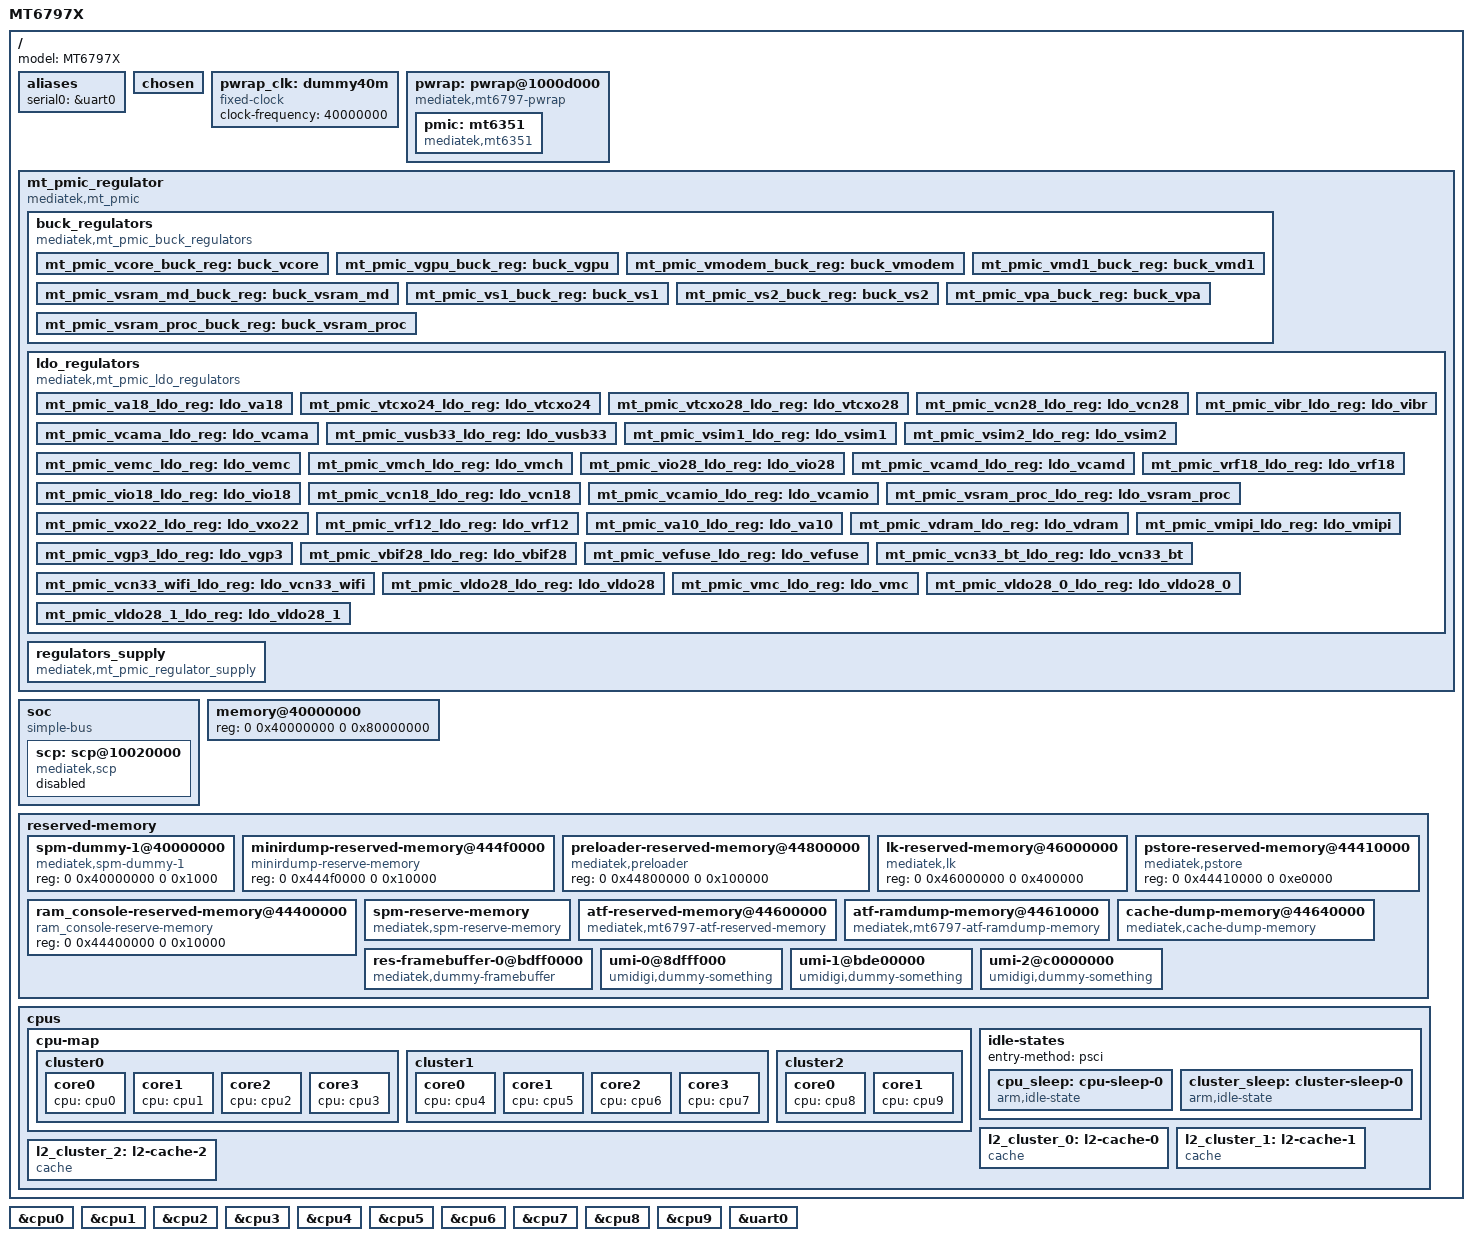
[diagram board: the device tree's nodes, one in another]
// SPDX-License-Identifier: GPL-2.0
/dts-v1/;

// This file will be copied to arch/arm64/boot/dts/gemini.dts by buildroot,
// so the include path must be relative to that.
#include "mediatek/mt6797.dtsi"
#include <dt-bindings/interrupt-controller/arm-gic.h>
#include <dt-bindings/power/mt6797-power.h>
#include <dt-bindings/reset/mt6797-resets.h>

/ {
	model = "MT6797X";

	aliases {
		serial0 = &uart0;
	};

	chosen {
		// Specifying cmdline here is useless, since they are
		// overwritten by LK. CMDLINE is overridden in kernel config.
	};

	// pwrap needs a pwrap clock, but MT6797 does not have one. Make a
	// fake clock to sate the module's hunger.
	pwrap_clk: dummy40m {
		compatible = "fixed-clock";
		clock-frequency = <40000000>;
		#clock-cells = <0>;
	};

	pwrap: pwrap@1000d000 {
		compatible = "mediatek,mt6797-pwrap";
		reg = <0 0x1000d000 0 0x1000>;
		reg-names = "pwrap";
		interrupts = <GIC_SPI 178 IRQ_TYPE_LEVEL_HIGH>;
		clocks = <&topckgen CLK_TOP_MUX_PMICSPI>, <&pwrap_clk>;
		clock-names = "spi", "wrap";
		resets = <&infrasys MT6797_INFRA_PMIC_WRAP_RST>;
		reset-names = "pwrap";
		pmic: mt6351 {
			compatible = "mediatek,mt6351";
		};
	};

	mt_pmic_regulator {
		compatible = "mediatek,mt_pmic";
		/*reg = <0x01>*/
		buck_regulators {
			compatible = "mediatek,mt_pmic_buck_regulators";
			mt_pmic_vcore_buck_reg: buck_vcore {
				regulator-name = "vcore";
				regulator-min-microvolt = <600000>;
				regulator-max-microvolt = <1393750>;
				regulator-ramp-delay = <6250>;
				regulator-enable-ramp-delay = <180>;
			};

			mt_pmic_vgpu_buck_reg: buck_vgpu {
				regulator-name = "vgpu";
				regulator-min-microvolt = <600000>;
				regulator-max-microvolt = <1393750>;
				regulator-ramp-delay = <6250>;
				regulator-enable-ramp-delay = <180>;
				regulator-always-on;
				regulator-boot-on;
			};

			mt_pmic_vmodem_buck_reg: buck_vmodem {
				regulator-name = "vmodem";
				regulator-min-microvolt = <600000>;
				regulator-max-microvolt = <1393750>;
				regulator-ramp-delay = <6250>;
				regulator-enable-ramp-delay = <180>;
				regulator-always-on;
				regulator-boot-on;
			};

			mt_pmic_vmd1_buck_reg: buck_vmd1 {
				regulator-name = "vmd1";
				regulator-min-microvolt = <600000>;
				regulator-max-microvolt = <1393750>;
				regulator-ramp-delay = <6250>;
				regulator-enable-ramp-delay = <180>;
				regulator-always-on;
				regulator-boot-on;
			};

			mt_pmic_vsram_md_buck_reg: buck_vsram_md {
				regulator-name = "vsram_md";
				regulator-min-microvolt = <600000>;
				regulator-max-microvolt = <1393750>;
				regulator-ramp-delay = <6250>;
				regulator-enable-ramp-delay = <180>;
				regulator-always-on;
				regulator-boot-on;
			};

			mt_pmic_vs1_buck_reg: buck_vs1 {
				regulator-name = "vs1";
				regulator-min-microvolt = <600000>;
				regulator-max-microvolt = <1393750>;
				regulator-ramp-delay = <6250>;
				regulator-enable-ramp-delay = <180>;
				regulator-always-on;
				regulator-boot-on;
			};

			mt_pmic_vs2_buck_reg: buck_vs2 {
				regulator-name = "vs2";
				regulator-min-microvolt = <600000>;
				regulator-max-microvolt = <1393750>;
				regulator-ramp-delay = <6250>;
				regulator-enable-ramp-delay = <180>;
				regulator-always-on;
				regulator-boot-on;
			};

			mt_pmic_vpa_buck_reg: buck_vpa {
				regulator-name = "vpa";
				regulator-min-microvolt = <600000>;
				regulator-max-microvolt = <1393750>;
				regulator-ramp-delay = <6250>;
				regulator-enable-ramp-delay = <180>;
				regulator-always-on;
				regulator-boot-on;
			};

			mt_pmic_vsram_proc_buck_reg: buck_vsram_proc {
				regulator-name = "vsram_proc";
				regulator-min-microvolt = <600000>;
				regulator-max-microvolt = <1393750>;
				regulator-ramp-delay = <6250>;
				regulator-enable-ramp-delay = <180>;
				regulator-always-on;
				regulator-boot-on;
			};

		};
	/* End of buck_regulators */
		ldo_regulators {
			compatible = "mediatek,mt_pmic_ldo_regulators";
			mt_pmic_va18_ldo_reg: ldo_va18 {
				regulator-name = "va18";
				regulator-min-microvolt = <1800000>;
				regulator-max-microvolt = <1800000>;
				regulator-enable-ramp-delay = <264>;
				regulator-boot-on;
			};

			mt_pmic_vtcxo24_ldo_reg: ldo_vtcxo24 {
				regulator-name = "vtcxo24";
				regulator-min-microvolt = <1800000>;
				regulator-max-microvolt = <2800000>;
				regulator-enable-ramp-delay = <110>;
				regulator-boot-on;
			};

			mt_pmic_vtcxo28_ldo_reg: ldo_vtcxo28 {
				regulator-name = "vtcxo28";
				regulator-min-microvolt = <1800000>;
				regulator-max-microvolt = <2800000>;
				regulator-enable-ramp-delay = <110>;
			};

			mt_pmic_vcn28_ldo_reg: ldo_vcn28 {
				regulator-name = "vcn28";
				regulator-min-microvolt = <1800000>;
				regulator-max-microvolt = <2800000>;
				regulator-enable-ramp-delay = <264>;
			};

			mt_pmic_vcama_ldo_reg: ldo_vcama {
				regulator-name = "vcama";
				regulator-min-microvolt = <1500000>;
				regulator-max-microvolt = <2800000>;
				regulator-enable-ramp-delay = <264>;
			};

			mt_pmic_vusb33_ldo_reg: ldo_vusb33 {
				regulator-name = "vusb33";
				regulator-min-microvolt = <3300000>;
				regulator-max-microvolt = <3300000>;
				regulator-enable-ramp-delay = <264>;
				regulator-boot-on;
			};

			mt_pmic_vsim1_ldo_reg: ldo_vsim1 {
				regulator-name = "vsim1";
				regulator-min-microvolt = <1700000>;
				regulator-max-microvolt = <3100000>;
				regulator-enable-ramp-delay = <264>;
			};

			mt_pmic_vsim2_ldo_reg: ldo_vsim2 {
				regulator-name = "vsim2";
				regulator-min-microvolt = <1700000>;
				regulator-max-microvolt = <3100000>;
				regulator-enable-ramp-delay = <264>;
			};

			mt_pmic_vemc_ldo_reg: ldo_vemc {
				regulator-name = "vemc_3v3";
				regulator-min-microvolt = <3000000>;
				regulator-max-microvolt = <3300000>;
				regulator-enable-ramp-delay = <44>;
				regulator-boot-on;
			};

			mt_pmic_vmch_ldo_reg: ldo_vmch {
				regulator-name = "vmch";
				regulator-min-microvolt = <3000000>;
				regulator-max-microvolt = <3300000>;
				regulator-enable-ramp-delay = <44>;
			};

			mt_pmic_vio28_ldo_reg: ldo_vio28 {
				regulator-name = "vio28";
				regulator-min-microvolt = <2800000>;
				regulator-max-microvolt = <2800000>;
				regulator-enable-ramp-delay = <264>;
				regulator-boot-on;
			};

			mt_pmic_vibr_ldo_reg: ldo_vibr {
				regulator-name = "vibr";
				regulator-min-microvolt = <1200000>;
				regulator-max-microvolt = <3300000>;
				regulator-enable-ramp-delay = <44>;
			};

			mt_pmic_vcamd_ldo_reg: ldo_vcamd {
				regulator-name = "vcamd";
				regulator-min-microvolt = <900000>;
				regulator-max-microvolt = <1210000>;
				regulator-enable-ramp-delay = <264>;
			};

			mt_pmic_vrf18_ldo_reg: ldo_vrf18 {
				regulator-name = "vrf18";
				regulator-min-microvolt = <1000000>;
				regulator-max-microvolt = <1810000>;
				regulator-enable-ramp-delay = <220>;
			};

			mt_pmic_vio18_ldo_reg: ldo_vio18 {
				regulator-name = "vio18";
				regulator-min-microvolt = <1800000>;
				regulator-max-microvolt = <1800000>;
				regulator-enable-ramp-delay = <264>;
				regulator-boot-on;
			};

			mt_pmic_vcn18_ldo_reg: ldo_vcn18 {
				regulator-name = "vcn18";
				regulator-min-microvolt = <1800000>;
				regulator-max-microvolt = <1800000>;
				regulator-enable-ramp-delay = <44>;
			};

			mt_pmic_vcamio_ldo_reg: ldo_vcamio {
				regulator-name = "vcamio";
				regulator-min-microvolt = <1200000>;
				regulator-max-microvolt = <1800000>;
				regulator-enable-ramp-delay = <220>;
			};

			mt_pmic_vsram_proc_ldo_reg: ldo_vsram_proc {
				regulator-name = "vsram_proc";
				regulator-min-microvolt = <600000>;
				regulator-max-microvolt = <1393750>;
				regulator-enable-ramp-delay = <220>;
				regulator-boot-on;
			};

			mt_pmic_vxo22_ldo_reg: ldo_vxo22 {
				regulator-name = "vxo22";
				regulator-min-microvolt = <1800000>;
				regulator-max-microvolt = <2800000>;
				regulator-enable-ramp-delay = <110>;
				regulator-boot-on;
			};

			mt_pmic_vrf12_ldo_reg: ldo_vrf12 {
				regulator-name = "vrf12";
				regulator-min-microvolt = <900000>;
				regulator-max-microvolt = <1200000>;
				regulator-enable-ramp-delay = <220>;
			};

			mt_pmic_va10_ldo_reg: ldo_va10 {
				regulator-name = "va10";
				regulator-min-microvolt = <900000>;
				regulator-max-microvolt = <1800000>;
				regulator-enable-ramp-delay = <264>;
				regulator-boot-on;
			};

			mt_pmic_vdram_ldo_reg: ldo_vdram {
				regulator-name = "vdram";
				regulator-min-microvolt = <900000>;
				regulator-max-microvolt = <1210000>;
				regulator-enable-ramp-delay = <264>;
			};

			mt_pmic_vmipi_ldo_reg: ldo_vmipi {
				regulator-name = "vmipi";
				regulator-min-microvolt = <900000>;
				regulator-max-microvolt = <1800000>;
				regulator-enable-ramp-delay = <264>;
			};

			mt_pmic_vgp3_ldo_reg: ldo_vgp3 {
				regulator-name = "vgp3";
				regulator-min-microvolt = <1000000>;
				regulator-max-microvolt = <1810000>;
				regulator-enable-ramp-delay = <264>;
			};

			mt_pmic_vbif28_ldo_reg: ldo_vbif28 {
				regulator-name = "vbif28";
				regulator-min-microvolt = <2800000>;
				regulator-max-microvolt = <2800000>;
				regulator-enable-ramp-delay = <264>;
			};

			mt_pmic_vefuse_ldo_reg: ldo_vefuse {
				regulator-name = "vefuse";
				regulator-min-microvolt = <1200000>;
				regulator-max-microvolt = <2200000>;
				regulator-enable-ramp-delay = <264>;
			};

			mt_pmic_vcn33_bt_ldo_reg: ldo_vcn33_bt {
				regulator-name = "vcn33_bt";
				regulator-min-microvolt = <3300000>;
				regulator-max-microvolt = <3600000>;
				regulator-enable-ramp-delay = <264>;
			};

			mt_pmic_vcn33_wifi_ldo_reg: ldo_vcn33_wifi {
				regulator-name = "vcn33_wifi";
				regulator-min-microvolt = <3300000>;
				regulator-max-microvolt = <3600000>;
				regulator-enable-ramp-delay = <264>;
			};

			mt_pmic_vldo28_ldo_reg: ldo_vldo28 {
				regulator-name = "vldo28";
				regulator-min-microvolt = <2800000>;
				regulator-max-microvolt = <2800000>;
				regulator-enable-ramp-delay = <264>;
			};

			mt_pmic_vmc_ldo_reg: ldo_vmc {
				regulator-name = "vmc";
				regulator-min-microvolt = <1200000>;
				regulator-max-microvolt = <3300000>;
				regulator-enable-ramp-delay = <44>;
			};

			mt_pmic_vldo28_0_ldo_reg: ldo_vldo28_0 {
				regulator-name = "vldo28_0";
				regulator-min-microvolt = <2800000>;
				regulator-max-microvolt = <2800000>;
				regulator-enable-ramp-delay = <264>;
			};

			mt_pmic_vldo28_1_ldo_reg: ldo_vldo28_1 {
				regulator-name = "vldo28_1";
				regulator-min-microvolt = <2800000>;
				regulator-max-microvolt = <2800000>;
				regulator-enable-ramp-delay = <264>;
			};

		};
/* End of ldo_regulators */
		regulators_supply {
			compatible = "mediatek,mt_pmic_regulator_supply";
			va18-supply = <&mt_pmic_va18_ldo_reg>;
			vtcxo24-supply = <&mt_pmic_vtcxo24_ldo_reg>;
			vtcxo28-supply = <&mt_pmic_vtcxo28_ldo_reg>;
			vsim1-supply = <&mt_pmic_vsim1_ldo_reg>;
			vsim2-supply = <&mt_pmic_vsim2_ldo_reg>;
			vemc-supply = <&mt_pmic_vemc_ldo_reg>;
			vmch-supply = <&mt_pmic_vmch_ldo_reg>;
			vmc-supply = <&mt_pmic_vmc_ldo_reg>;
			vio28-supply = <&mt_pmic_vio28_ldo_reg>;
			vibr-supply = <&mt_pmic_vibr_ldo_reg>;
			vrf18-supply = <&mt_pmic_vrf18_ldo_reg>;
			vio18-supply = <&mt_pmic_vio18_ldo_reg>;
			vsram_proc-supply = <&mt_pmic_vsram_proc_ldo_reg>;
			vxo22-supply = <&mt_pmic_vxo22_ldo_reg>;
			vrf12-supply = <&mt_pmic_vrf12_ldo_reg>;
			vdram-supply = <&mt_pmic_vdram_ldo_reg>;
			vmipi-supply = <&mt_pmic_vmipi_ldo_reg>;
			vbif28-supply = <&mt_pmic_vbif28_ldo_reg>;
			vefuse-supply = <&mt_pmic_vefuse_ldo_reg>;
			vcn18-supply = <&mt_pmic_vcn18_ldo_reg>;
			vcn28-supply = <&mt_pmic_vcn28_ldo_reg>;
			vcn33_bt-supply = <&mt_pmic_vcn33_bt_ldo_reg>;
			vcn33_wifi-supply = <&mt_pmic_vcn33_wifi_ldo_reg>;
			mhl_12v-supply = <&mt_pmic_vgp3_ldo_reg>;
		};
/* End of regulators_supply */
	};
/* End of mt_pmic_regulator */

	soc {
		compatible = "simple-bus";
		#address-cells = <1>;
		#size-cells = <1>;
		ranges = <0 0 0 0xffffffff>;

		// This node is required by MediaTek's LK bootloader.
		scp: scp@10020000 {
			compatible = "mediatek,scp";
			status = "disabled";
			reg = <0x10020000 0x80000>,
				<0x100a0000 0x1000>,
				<0x100a4000 0x1000>;
			interrupts = <GIC_SPI 199 IRQ_TYPE_LEVEL_HIGH>;
		};
	};

	memory@40000000 {
		device_type = "memory";
		// It won't matter much what we write here, since the bootloader
		// overwrites the reg option anyway.
		reg = <0 0x40000000 0 0x80000000>;
	};

	reserved-memory {
		#address-cells = <2>;
		#size-cells = <2>;
		ranges;

		spm-dummy-1@40000000 {
			compatible = "mediatek,spm-dummy-1";
			reg = <0 0x40000000 0 0x1000>;
		};

		minirdump-reserved-memory@444f0000 {
			compatible = "minirdump-reserve-memory";
			reg = <0 0x444f0000 0 0x10000>;
		};

		preloader-reserved-memory@44800000 {
			compatible = "mediatek,preloader";
			reg = <0 0x44800000 0 0x100000>;
		};

		lk-reserved-memory@46000000 {
			compatible = "mediatek,lk";
			reg = <0 0x46000000 0 0x400000>;
		};

		ram_console-reserved-memory@44400000 {
			compatible = "ram_console-reserve-memory";
			reg = <0 0x44400000 0 0x10000>;
		};

		pstore-reserved-memory@44410000 {
			compatible = "mediatek,pstore";
			reg = <0 0x44410000 0 0xe0000>;
			/*console-size = <0 0x40000>;*/
		};

		spm-reserve-memory {
			compatible = "mediatek,spm-reserve-memory";
			no-map;
			size = <0 0x16000>; /* PCM_FIRMWARE_SIZE * DYNA_LOAD_PCM_MAX = 8K * 11 */
			alignment = <0 0x10000>;
			alloc-ranges = <0 0x40000000 0 0x80000000>;
		};

		atf-reserved-memory@44600000 {
			compatible = "mediatek,mt6797-atf-reserved-memory";
			no-map;
			reg = <0 0x44600000 0 0x10000>;
		};

		atf-ramdump-memory@44610000 {
			compatible = "mediatek,mt6797-atf-ramdump-memory";
			no-map;
			reg = <0 0x44610000 0 0x30000>;
		};

		cache-dump-memory@44640000 {
			compatible = "mediatek,cache-dump-memory";
			no-map;
			reg = <0 0x44640000 0 0x30000>;
		};

		// These areas are not declared as reserved by the bootloader,
		// are not in the I/O range. They are ioremapped by the video
		// driver (during late boot).
		res-framebuffer-0@bdff0000 {
			compatible = "mediatek,dummy-framebuffer";
			no-map;
			reg = <0 0xbdff0000 0 0x01f90000>;
		};

		umi-0@8dfff000 {
			compatible = "umidigi,dummy-something";
			no-map;
			reg = <0 0x8dfff000 0 0x1000>;
		};

		umi-1@bde00000 {
			compatible = "umidigi,dummy-something";
			no-map;
			reg = <0 0xbde00000 0 0x10000>;
		};

		umi-2@c0000000 {
			compatible = "umidigi,dummy-something";
			no-map;
			// WTF 1.5 gigs?
			reg = <0 0xc0000000 0 0x60000000>;
		};
	};

	cpus {
		cpu-map {
			cluster0 {
				 core0 { cpu = <&cpu0>; };
				 core1 { cpu = <&cpu1>; };
				 core2 { cpu = <&cpu2>; };
				 core3 { cpu = <&cpu3>; };
			};
			cluster1 {
				 core0 { cpu = <&cpu4>; };
				 core1 { cpu = <&cpu5>; };
				 core2 { cpu = <&cpu6>; };
				 core3 { cpu = <&cpu7>; };
			};
			cluster2 {
				 core0 { cpu = <&cpu8>; };
				 core1 { cpu = <&cpu9>; };
			};
		};

		idle-states {
			entry-method = "psci";

			cpu_sleep: cpu-sleep-0 {
				compatible = "arm,idle-state";
				arm,psci-suspend-param = <0x0010000>;
				entry-latency-us = <600>;
				exit-latency-us = <600>;
				min-residency-us = <1200>;
			};
			cluster_sleep: cluster-sleep-0 {
				compatible = "arm,idle-state";
				arm,psci-suspend-param = <0x1010000>;
				entry-latency-us = <800>;
				exit-latency-us = <1000>;
				min-residency-us = <2000>;
			};
		};

		l2_cluster_0: l2-cache-0 {
			compatible = "cache";
			cache-size = <0x80000>;
			cache-line-size = <64>;
			cache-sets = <512>;
		};

		l2_cluster_1: l2-cache-1 {
			compatible = "cache";
			cache-size = <0x80000>;
			cache-line-size = <64>;
			cache-sets = <512>;
		};

		l2_cluster_2: l2-cache-2 {
			compatible = "cache";
			cache-size = <0x80000>;
			cache-line-size = <64>;
			cache-sets = <512>;
		};
	};
};

// clock-frequency must be specified for each CPU. If it is omitted, MediaTek's
// LK bootloader might read uninitialized memory and perhaps overwrite some
// random properties in the device tree.

// Slow Cortex-A53 cluster
&cpu0 {
	clock-frequency = <1391000000>;
	//cpu-idle-states = <&cpu_sleep &cluster_sleep>;
	i-cache-size = <0x8000>;
	i-cache-line-size = <64>;
	i-cache-sets = <256>;
	d-cache-size = <0x8000>;
	d-cache-line-size = <64>;
	d-cache-sets = <128>;
	next-level-cache = <&l2_cluster_0>;
};
&cpu1 {
	clock-frequency = <1391000000>;
	//cpu-idle-states = <&cpu_sleep &cluster_sleep>;
	i-cache-size = <0x8000>;
	i-cache-line-size = <64>;
	i-cache-sets = <256>;
	d-cache-size = <0x8000>;
	d-cache-line-size = <64>;
	d-cache-sets = <128>;
	next-level-cache = <&l2_cluster_0>;
};
&cpu2 {
	clock-frequency = <1391000000>;
	//cpu-idle-states = <&cpu_sleep &cluster_sleep>;
	i-cache-size = <0x8000>;
	i-cache-sets = <256>;
	i-cache-line-size = <64>;
	d-cache-size = <0x8000>;
	d-cache-line-size = <64>;
	d-cache-sets = <128>;
	next-level-cache = <&l2_cluster_0>;
};
&cpu3 {
	clock-frequency = <1391000000>;
	//cpu-idle-states = <&cpu_sleep &cluster_sleep>;
	i-cache-size = <0x8000>;
	i-cache-line-size = <64>;
	i-cache-sets = <256>;
	d-cache-size = <0x8000>;
	d-cache-line-size = <64>;
	d-cache-sets = <128>;
	next-level-cache = <&l2_cluster_0>;
};

// Fast Cortex-A53 cluster
&cpu4 {
	clock-frequency = <1950000000>;
	//cpu-idle-states = <&cpu_sleep &cluster_sleep>;
	i-cache-size = <0x8000>;
	i-cache-line-size = <64>;
	i-cache-sets = <256>;
	d-cache-size = <0x8000>;
	d-cache-line-size = <64>;
	d-cache-sets = <128>;
	next-level-cache = <&l2_cluster_1>;
};
&cpu5 {
	clock-frequency = <1950000000>;
	//cpu-idle-states = <&cpu_sleep &cluster_sleep>;
	i-cache-size = <0x8000>;
	i-cache-line-size = <64>;
	i-cache-sets = <256>;
	d-cache-size = <0x8000>;
	d-cache-line-size = <64>;
	d-cache-sets = <128>;
	next-level-cache = <&l2_cluster_1>;
};
&cpu6 {
	clock-frequency = <1950000000>;
	//cpu-idle-states = <&cpu_sleep &cluster_sleep>;
	i-cache-size = <0x8000>;
	i-cache-line-size = <64>;
	i-cache-sets = <256>;
	d-cache-size = <0x8000>;
	d-cache-line-size = <64>;
	d-cache-sets = <128>;
	next-level-cache = <&l2_cluster_1>;
};
&cpu7 {
	clock-frequency = <1950000000>;
	//cpu-idle-states = <&cpu_sleep &cluster_sleep>;
	i-cache-size = <0x8000>;
	i-cache-line-size = <64>;
	i-cache-sets = <256>;
	d-cache-size = <0x8000>;
	d-cache-line-size = <64>;
	d-cache-sets = <128>;
	next-level-cache = <&l2_cluster_1>;
};

// Fast Cortex-A72 cluster
&cpu8 {
	clock-frequency = <2288000000>;
	//cpu-idle-states = <&cpu_sleep &cluster_sleep>;

	i-cache-size = <0xc000>;
	i-cache-line-size = <64>;
	i-cache-sets = <256>;

	d-cache-size = <0x8000>;
	d-cache-line-size = <64>;
	d-cache-sets = <256>;
	next-level-cache = <&l2_cluster_2>;
};
&cpu9 {
	clock-frequency = <2288000000>;
	//cpu-idle-states = <&cpu_sleep &cluster_sleep>;

	i-cache-size = <0xc000>;
	i-cache-line-size = <64>;
	i-cache-sets = <256>;

	d-cache-size = <0x8000>;
	d-cache-line-size = <64>;
	d-cache-sets = <256>;
	next-level-cache = <&l2_cluster_2>;
};

&uart0 {
	status = "okay";
};
